AUTOSAR XML (schema 00044)
package /ComponentTypes
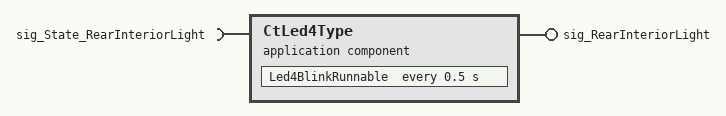
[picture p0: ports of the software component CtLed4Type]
  application sw component type CtLed4Type
    provide port sig_RearInteriorLight: nonqueued-sender-com-spec{data-element=RearInteriorLight, init-value=0}, provided-interface=sig_RearInteriorLight
    require port sig_State_RearInteriorLight: nonqueued-receiver-com-spec{data-element=State_RearInteriorLight, filter=data-filter-type=ALWAYS, init-value=0}, required-interface=sig_State_RearInteriorLight
    behavior CtLed4Type_InternalBehavior
      timing event TMT_Led4BlinkRunnable: start-on-event=Led4BlinkRunnable, period=0.5
      runnable Led4BlinkRunnable
        data-receive-point-by-arguments:
          access REC_sig_State_RearInteriorLight_State_RearInteriorLight: accessed-variable=sig_State_RearInteriorLight.State_RearInteriorLight
        data-send-points:
          access SEND_sig_RearInteriorLight_RearInteriorLight: accessed-variable=sig_RearInteriorLight.RearInteriorLight
  swc implementation CtLed4Type_Implementation: behavior=CtLed4Type_InternalBehavior
